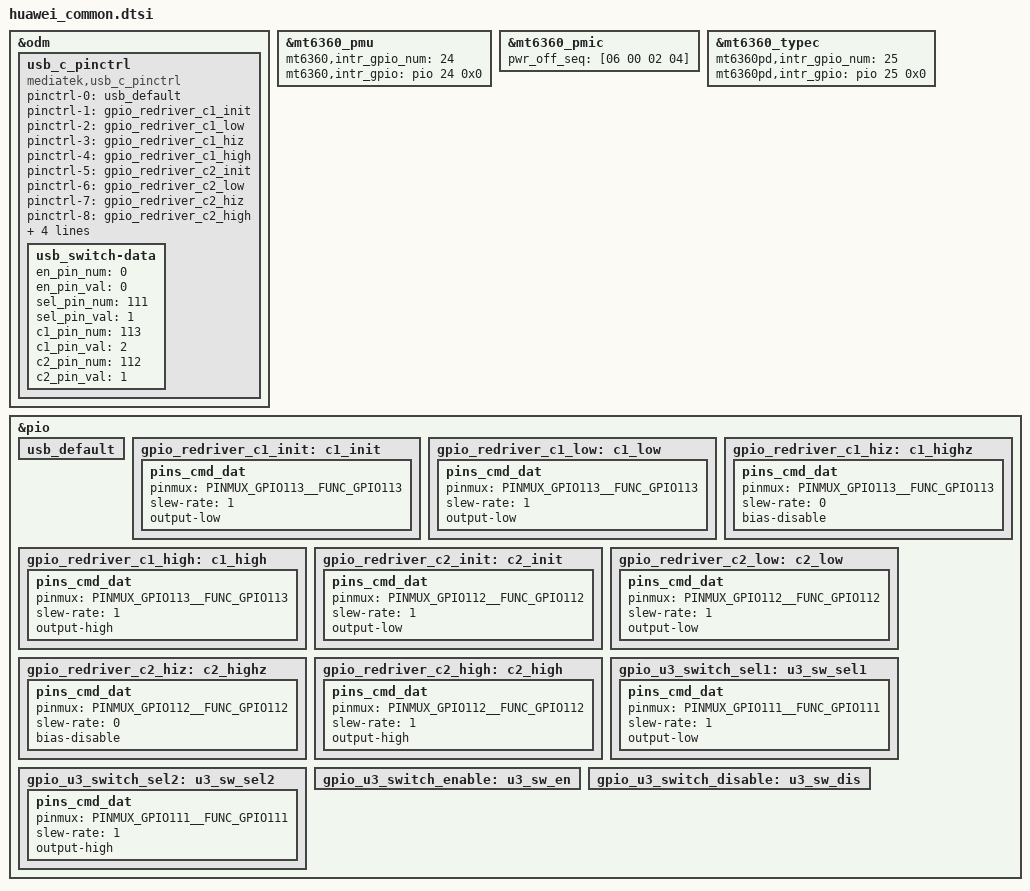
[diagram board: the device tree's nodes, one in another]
#include "huawei_dev_detect/huawei_dev_detect.dtsi"
#include "huawei_antenna_gpio_detect/huawei_antenna_gpio_detect.dtsi"
#include <dt-bindings/interrupt-controller/irq.h>
#include <dt-bindings/interrupt-controller/arm-gic.h>
#include <dt-bindings/pinctrl/mt6873-pinfunc.h>
&odm {
	usb_c_pinctrl:usb_c_pinctrl {
		compatible = "mediatek,usb_c_pinctrl";
	};
};
&mt6360_pmu {
	mt6360,intr_gpio_num = <24>; /* direct defined GPIO num */
	mt6360,intr_gpio = <&pio 24 0x0>;
};

&mt6360_pmic {
	pwr_off_seq = [06 00 02 04];
};

&mt6360_typec {
	mt6360pd,intr_gpio_num = <25>; /* direct defined GPIO num */
	mt6360pd,intr_gpio = <&pio 25 0x0>;
};

/* USB SWITCH GPIO start */
&pio {
	usb_default: usb_default {
	};

	gpio_redriver_c1_init: c1_init {
		pins_cmd_dat {
			pinmux = <PINMUX_GPIO113__FUNC_GPIO113>;
			slew-rate = <1>;
			output-low;
		};
	};

	gpio_redriver_c1_low: c1_low {
		pins_cmd_dat {
			pinmux = <PINMUX_GPIO113__FUNC_GPIO113>;
			slew-rate = <1>;
			output-low;
		};
	};

	gpio_redriver_c1_hiz: c1_highz {
		pins_cmd_dat {
			pinmux = <PINMUX_GPIO113__FUNC_GPIO113>;
			slew-rate= <0>;
			bias-disable;
		};
	};

	gpio_redriver_c1_high: c1_high {
		pins_cmd_dat {
			pinmux = <PINMUX_GPIO113__FUNC_GPIO113>;
			slew-rate = <1>;
			output-high;
		};
	};

	gpio_redriver_c2_init: c2_init {
		pins_cmd_dat {
			pinmux = <PINMUX_GPIO112__FUNC_GPIO112>;
			slew-rate = <1>;
			output-low;
		};
	};

	gpio_redriver_c2_low: c2_low {
		pins_cmd_dat {
			pinmux = <PINMUX_GPIO112__FUNC_GPIO112>;
			slew-rate = <1>;
			output-low;
		};
	};

	gpio_redriver_c2_hiz: c2_highz {
		pins_cmd_dat {
			pinmux = <PINMUX_GPIO112__FUNC_GPIO112>;
			slew-rate= <0>;
			bias-disable;
		};
	};

	gpio_redriver_c2_high: c2_high {
		pins_cmd_dat {
			pinmux = <PINMUX_GPIO112__FUNC_GPIO112>;
			slew-rate = <1>;
			output-high;
		};
	};

	gpio_u3_switch_sel1: u3_sw_sel1 {
		pins_cmd_dat {
			pinmux = <PINMUX_GPIO111__FUNC_GPIO111>;
			slew-rate = <1>;
			output-low;
		};
	};

	gpio_u3_switch_sel2: u3_sw_sel2 {
		pins_cmd_dat {
			pinmux = <PINMUX_GPIO111__FUNC_GPIO111>;
			slew-rate = <1>;
			output-high;
		};
	};

	gpio_u3_switch_enable: u3_sw_en {
	};

	gpio_u3_switch_disable: u3_sw_dis {
	};
};

&usb_c_pinctrl {
	pinctrl-names = "usb_default",
		"redrv_c1_init",
		"redrv_c1_low",
		"redrv_c1_hiz",
		"redrv_c1_high",
		"redrv_c2_init",
		"redrv_c2_low",
		"redrv_c2_hiz",
		"redrv_c2_high",
		"switch_sel1",
		"switch_sel2",
		"switch_enable",
		"switch_disable";

	pinctrl-0 = <&usb_default>;
	pinctrl-1 = <&gpio_redriver_c1_init>;
	pinctrl-2 = <&gpio_redriver_c1_low>;
	pinctrl-3 = <&gpio_redriver_c1_hiz>;
	pinctrl-4 = <&gpio_redriver_c1_high>;
	pinctrl-5 = <&gpio_redriver_c2_init>;
	pinctrl-6 = <&gpio_redriver_c2_low>;
	pinctrl-7 = <&gpio_redriver_c2_hiz>;
	pinctrl-8 = <&gpio_redriver_c2_high>;
	pinctrl-9 = <&gpio_u3_switch_sel1>;
	pinctrl-10 = <&gpio_u3_switch_sel2>;
	pinctrl-11 = <&gpio_u3_switch_enable>;
	pinctrl-12 = <&gpio_u3_switch_disable>;
	status = "okay";

	usb_switch-data {
		en_pin_num = <0>;
		en_pin_val = <0>;
		sel_pin_num = <111>;
		sel_pin_val = <1>;
		c1_pin_num = <113>;
		c1_pin_val = <2>;
		c2_pin_num = <112>;
		c2_pin_val = <1>;
	};
};
/* USB SWITCH GPIO end */
